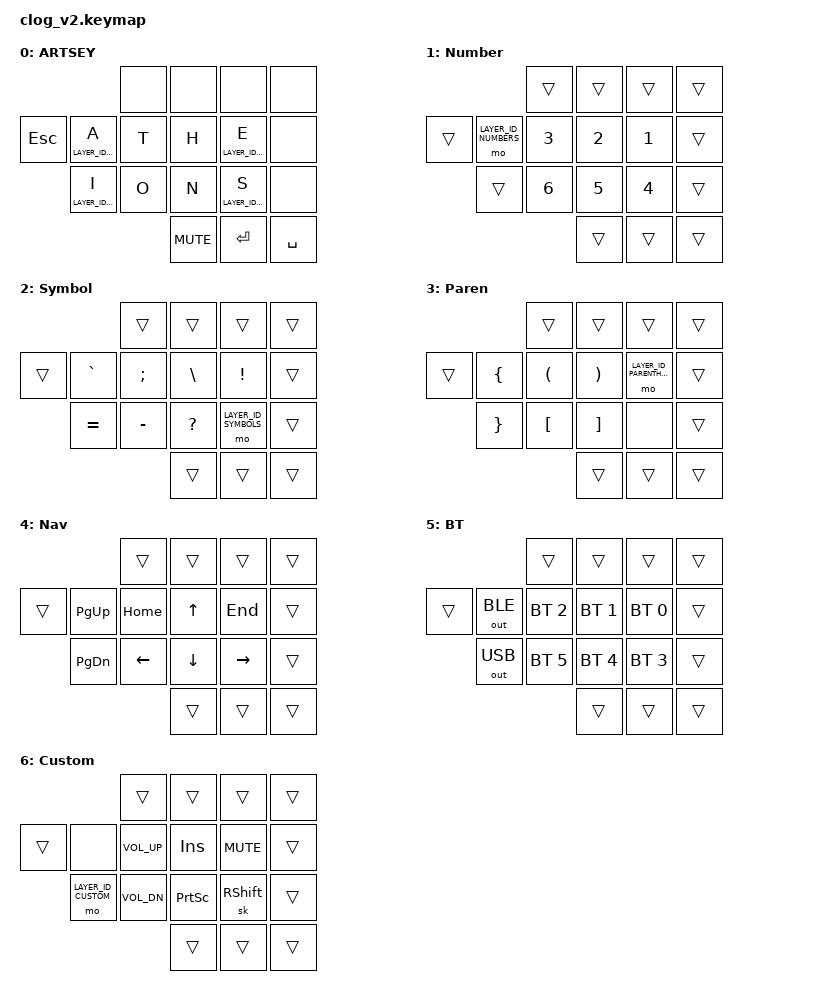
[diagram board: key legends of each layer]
#include <behaviors.dtsi>
#include <dt-bindings/zmk/keys.h>
#include <dt-bindings/zmk/bt.h>

#define KEY_E 8
#define KEY_H 7
#define KEY_T 6
#define KEY_A 5
#define KEY_S 12
#define KEY_N 11
#define KEY_O 10
#define KEY_I 9

/*
 * Copyright (c) 2021 Mike "KemoNine" Crosson
 *
 * SPDX-License-Identifier: MIT
 */

#include <behaviors.dtsi>
#include <dt-bindings/zmk/keys.h>
#include <dt-bindings/zmk/outputs.h>

/*****************************************
 * Setting up ARTSEY comboing
 *   - Enabled right OR left handed orientation
 *   - Please note: A/E key positions should be on your INDEX finger
 *     - The online reference is for right handed use
 *     - When using the ARTSEY layout left handed you'll want to ensure your keypositions are flipped along the Y axis
 *   - Update/adjust the key positions using your boards keymap 
 *     - See below for additional details
 *   - YOU MUST SET THE FOLLOWING CONFIG VALUES FOR THIS SETUP TO WORK PROPERLY IN YOUR BOARDS .conf FILE
 *     - CONFIG_ZMK_COMBO_MAX_COMBOS_PER_KEY=16
 *     - CONFIG_ZMK_COMBO_MAX_KEYS_PER_COMBO=8
 *     - CONFIG_ZMK_COMBO_MAX_PRESSED_COMBOS=8
 *****************************************/

// ARTS Row
// #define 8 0
// #define 7 1
// #define 6 2
// #define 3 3
// EYIO Row
// #define 12 4
// #define 11 5
// #define 10 6
// #define 9 7

/*****************************************
 * Define custom BT layer extra keys
 *
 * You can override the 2 blank keys on the BT select layer by copy/pasting the below into your keymap
 *     *before* including the artsey.dtsfile
 * Once added to your keymap you can adjust these 2 keys as you see fit
*****************************************/
#if !defined ARTSEY_BT_TOP
#define ARTSEY_BT_TOP &out OUT_BLE
#endif
#if !defined ARTSEY_BT_BOTTOM
#define ARTSEY_BT_BOTTOM &out OUT_USB
#endif

/*****************************************
 * Define how long it takes for the combos/holds to 'time out'
 * See documentation on "combos" for more detail
 * THE COMBO TIMEOUTS MUST BE THE SAME
 *    https://github.com/zmkfirmware/zmk/issues/905
 *****************************************/
#if !defined TIMEOUT_COMBO_2
#define TIMEOUT_COMBO_2 175
#endif
#if !defined TIMEOUT_COMBO_3
#define TIMEOUT_COMBO_3 175
#endif
#if !defined TIMEOUT_COMBO_4
#define TIMEOUT_COMBO_4 175
#endif
#if !defined TIMEOUT_LAYER_HOLD
#define TIMEOUT_LAYER_HOLD 200
#endif
#if !defined TIMEOUT_STICKY_LEADER_KEY
#define TIMEOUT_STICKY_LEADER_KEY 5000
#endif
&sk {
	release-after-ms = <TIMEOUT_STICKY_LEADER_KEY>;
};
&sl { 
	release-after-ms = <TIMEOUT_STICKY_LEADER_KEY>;
};

/*****************************************
 * Define custom layer
 *
 * You can override this layer by copy/pasting the into your keymap *before* including the artsey.dtsi file
 * Once added to your keymap you can adjust as you see fit
*****************************************/

/*****************************************
 * Layer IDs used by the ARTSEY keymap
 * Do NOT change these and do NOT change the order of the layers as shown below
 *****************************************/
#define LAYER_ID_GLOBAL -1
#define LAYER_ID_BASE 0
#define LAYER_ID_NUMBERS 1
#define LAYER_ID_SYMBOLS 2
#define LAYER_ID_PARENTHETICALS 3
#define LAYER_ID_NAVIGATION 4
#define LAYER_ID_BT_SEL 5
#define LAYER_ID_CUSTOM 6
#define LAYER_ID_BIG_SYM 7
#define LAYER_ID_BIG_FUNCTION 8

/*****************************************
 * Standard ARTSEY combo definitions
 * These should NOT be changed and are global in scope
 *****************************************/
/ {
	combos {
		compatible = "zmk,combos";
		/*****************************************
		 * 2 key combos
		 *****************************************/
		combo_enter      { timeout-ms = <TIMEOUT_COMBO_2>; key-positions = <8 12>; bindings = <&kp ENTER>; };
		combo_control    { timeout-ms = <TIMEOUT_COMBO_2>; key-positions = <12 3>; bindings = <&sk LCTRL>; };
		combo_gui        { timeout-ms = <TIMEOUT_COMBO_2>; key-positions = <11 3>; bindings = <&sk LGUI>; };
		combo_alt        { timeout-ms = <TIMEOUT_COMBO_2>; key-positions = <10 3>; bindings = <&sk LALT>; };
		combo_backspace  { timeout-ms = <TIMEOUT_COMBO_2>; key-positions = <12 7>; bindings = <&kp BACKSPACE>; };
		combo_delete     { timeout-ms = <TIMEOUT_COMBO_2>; key-positions = <10 7>; bindings = <&kp DELETE>; };
		combo_shift_lock { timeout-ms = <TIMEOUT_COMBO_2>; key-positions = <7 11>; bindings = <&kp LSHFT>; };

		combo_b           { layers = <LAYER_ID_BASE>; timeout-ms = <TIMEOUT_COMBO_2>; key-positions = <12 9>; bindings = <&kp B>; };
		combo_c           { layers = <LAYER_ID_BASE>; timeout-ms = <TIMEOUT_COMBO_2>; key-positions = <12 11>; bindings = <&kp C>; };
		combo_n           { layers = <LAYER_ID_BASE>; timeout-ms = <TIMEOUT_COMBO_2>; key-positions = <10 9>; bindings = <&kp Y>; };
		combo_f           { layers = <LAYER_ID_BASE>; timeout-ms = <TIMEOUT_COMBO_2>; key-positions = <8 7>; bindings = <&kp F>; };
		combo_g           { layers = <LAYER_ID_BASE>; timeout-ms = <TIMEOUT_COMBO_2>; key-positions = <7 6>; bindings = <&kp G>; };
		combo_u           { layers = <LAYER_ID_BASE>; timeout-ms = <TIMEOUT_COMBO_2>; key-positions = <11 10>; bindings = <&kp U>; };
		combo_h           { layers = <LAYER_ID_BASE>; timeout-ms = <TIMEOUT_COMBO_2>; key-positions = <12 10>; bindings = <&kp R>; };
		combo_v           { layers = <LAYER_ID_BASE>; timeout-ms = <TIMEOUT_COMBO_2>; key-positions = <7 3>; bindings = <&kp V>; };
		combo_j           { layers = <LAYER_ID_BASE>; timeout-ms = <TIMEOUT_COMBO_2>; key-positions = <6 3>; bindings = <&kp J>; };
		combo_w           { layers = <LAYER_ID_BASE>; timeout-ms = <TIMEOUT_COMBO_2>; key-positions = <8 3>; bindings = <&kp W>; };
		combo_k           { layers = <LAYER_ID_BASE>; timeout-ms = <TIMEOUT_COMBO_2>; key-positions = <11 9>; bindings = <&kp K>; };
		combo_comma       { layers = <LAYER_ID_BASE>; timeout-ms = <TIMEOUT_COMBO_2>; key-positions = <8 11>; bindings = <&kp COMMA>; };
		combo_period      { layers = <LAYER_ID_BASE>; timeout-ms = <TIMEOUT_COMBO_2>; key-positions = <8 10>; bindings = <&kp PERIOD>; };
		combo_slash       { layers = <LAYER_ID_BASE>; timeout-ms = <TIMEOUT_COMBO_2>; key-positions = <8 9>; bindings = <&kp SLASH>; };
		combo_exclamation { layers = <LAYER_ID_BASE>; timeout-ms = <TIMEOUT_COMBO_2>; key-positions = <6 10>; bindings = <&kp EXCL>; };
		
		combo_seven { layers = <LAYER_ID_NUMBERS>; timeout-ms = <TIMEOUT_COMBO_2>; key-positions = <8 7>; bindings = <&kp N7>; };
		combo_eight { layers = <LAYER_ID_NUMBERS>; timeout-ms = <TIMEOUT_COMBO_2>; key-positions = <7 6>; bindings = <&kp N8>; };
		combo_nine  { layers = <LAYER_ID_NUMBERS>; timeout-ms = <TIMEOUT_COMBO_2>; key-positions = <12 11>; bindings = <&kp N9>; };
		combo_zero  { layers = <LAYER_ID_NUMBERS>; timeout-ms = <TIMEOUT_COMBO_2>; key-positions = <11 10>; bindings = <&kp N0>; };

		/*****************************************
		 * 3 key combos
		 *****************************************/
		combo_esc              { timeout-ms = <TIMEOUT_COMBO_3>; key-positions = <8 7 9>; bindings = <&kp ESC>; };
		combo_layer_navigation { timeout-ms = <TIMEOUT_COMBO_3>; key-positions = <7 12 10>; bindings = <&tog LAYER_ID_NAVIGATION>; };

		combo_m            { layers = <LAYER_ID_BASE>; timeout-ms = <TIMEOUT_COMBO_3>; key-positions = <11 10 9>; bindings = <&kp M>; };
		combo_d            { layers = <LAYER_ID_BASE>; timeout-ms = <TIMEOUT_COMBO_3>; key-positions = <8 7 6>; bindings = <&kp D>; };
		combo_p            { layers = <LAYER_ID_BASE>; timeout-ms = <TIMEOUT_COMBO_3>; key-positions = <12 10 9>; bindings = <&kp P>; };
		combo_q            { layers = <LAYER_ID_BASE>; timeout-ms = <TIMEOUT_COMBO_3>; key-positions = <8 6 3>; bindings = <&kp Q>; };
		combo_x            { layers = <LAYER_ID_BASE>; timeout-ms = <TIMEOUT_COMBO_3>; key-positions = <7 6 3>; bindings = <&kp X>; };
		combo_l            { layers = <LAYER_ID_BASE>; timeout-ms = <TIMEOUT_COMBO_3>; key-positions = <12 11 10>; bindings = <&kp L>; };
		combo_single_quote { layers = <LAYER_ID_BASE>; timeout-ms = <TIMEOUT_COMBO_3>; key-positions = <8 11 10>; bindings = <&kp SQT>; };
		
		/*****************************************
		 * 4 key combos
		 *****************************************/
		combo_tab             { timeout-ms = <TIMEOUT_COMBO_4>; key-positions = <8 7 6 9>; bindings = <&kp TAB>; };
		combo_space           { timeout-ms = <TIMEOUT_COMBO_4>; key-positions = <12 11 10 9>; bindings = <&kp SPACE>; };
		combo_shift           { timeout-ms = <TIMEOUT_COMBO_4>; key-positions = <12 7 6 3>; bindings = <&sk LSHFT>; };
		combo_layer_bt_select { timeout-ms = <TIMEOUT_COMBO_4>; key-positions = <8 12 3 9>; bindings = <&tog LAYER_ID_BT_SEL>; };
		combo_bt_clr          { timeout-ms = <TIMEOUT_COMBO_4>; key-positions = <7 11 6 10>; bindings = <&bt BT_CLR>; };

		combo_z         { layers = <LAYER_ID_BASE>; timeout-ms = <TIMEOUT_COMBO_4>; key-positions = <8 7 6 3>; bindings = <&kp Z>; };
		combo_caps_lock { layers = <LAYER_ID_BASE>; timeout-ms = <TIMEOUT_COMBO_4>; key-positions = <9 10 11 8>; bindings = <&kp CAPS>; };
	};
};

/*****************************************
 * Standard ARTSEY layer activation definitions
 * These should NOT be changed and are global in scope
 *****************************************/
/ {
	behaviors {
		layer_base_kp: layer_base_kp { compatible = "zmk,behavior-hold-tap"; label = "layer_base_kp"; 
						#binding-cells = <2>; tapping_term_ms = <TIMEOUT_LAYER_HOLD>; flavor = "tap-preferred"; 
						bindings = <&mo>, <&kp>; };
		layer_numbers_kp: layer_numbers_kp { compatible = "zmk,behavior-hold-tap"; label = "layer_numbers_kp"; 
						#binding-cells = <2>; tapping_term_ms = <TIMEOUT_LAYER_HOLD>; flavor = "tap-preferred"; 
						bindings = <&mo>, <&kp>; };
		layer_symbols_kp: layer_symbols_kp { compatible = "zmk,behavior-hold-tap"; label = "layer_symbols_kp"; 
						#binding-cells = <2>; tapping_term_ms = <TIMEOUT_LAYER_HOLD>; flavor = "tap-preferred"; 
						bindings = <&mo>, <&kp>; };
		layer_parentheticals_kp: layer_parentheticals_kp { compatible = "zmk,behavior-hold-tap"; label = "layer_parentheticals_kp";
						#binding-cells = <2>; tapping_term_ms = <TIMEOUT_LAYER_HOLD>; flavor = "tap-preferred";
						bindings = <&mo>, <&kp>; };
		layer_custom_kp: layer_custom_kp { compatible = "zmk,behavior-hold-tap"; label = "layer_custom_kp";
						#binding-cells = <2>; tapping_term_ms = <TIMEOUT_LAYER_HOLD>; flavor = "tap-preferred";
						bindings = <&mo>, <&kp>; };
		ctrl_alt_kp: ctrl_alt_kp { compatible = "zmk,behavior-hold-tap"; label = "ctrl_alt_kp";
						#binding-cells = <2>; tapping_term_ms = <TIMEOUT_LAYER_HOLD>; flavor = "tap-preferred";
						bindings = <&sk>, <&sk>; };
	};
};



/ {
    keymap {
        compatible = "zmk,keymap";
        base {
            label = "ARTSEY";
            bindings = <
                                                         &none &none       &none                                              &none
            &kp ESC &layer_numbers_kp LAYER_ID_NUMBERS A &kp T &kp H       &layer_parentheticals_kp LAYER_ID_PARENTHETICALS E &none
                    &layer_custom_kp LAYER_ID_CUSTOM I   &kp O &kp N       &layer_symbols_kp LAYER_ID_SYMBOLS S               &none
                                                               &kp C_MUTE  &kp ENTER                                          &kp SPC
            >;

			sensor-bindings = <&inc_dec_kp PG_DN PG_UP>;
        };
		numbers {
			label = "Number";
			bindings = <
				                         &trans &trans &trans &trans
			&trans &mo LAYER_ID_NUMBERS  &kp N3 &kp N2 &kp N1 &trans
				   &trans                &kp N6 &kp N5 &kp N4 &trans
                                                &trans &trans &trans
				
			>;
		};
		symbols {
			label = "Symbol";
			bindings = <
				             &trans    &trans    &trans               &trans
			&trans &kp GRAVE &kp SEMI  &kp BSLH  &kp EXCL             &trans
				   &kp EQUAL &kp MINUS &kp QMARK &mo LAYER_ID_SYMBOLS &trans
                                       &trans    &trans               &trans
			>;
		};
		parentheticals {
			label = "Paren";
			bindings = <
			                &trans   &trans   &trans                      &trans
			&trans &kp LBRC &kp LPAR &kp RPAR &mo LAYER_ID_PARENTHETICALS &trans
			       &kp RBRC &kp LBKT &kp RBKT &none                       &trans
                                     &trans   &trans                      &trans
			>;
		};
		navigation {
			label = "Nav";
			bindings = <
				             &trans   &trans   &trans    &trans
			&trans &kp PG_UP &kp HOME &kp UP   &kp END   &trans
				   &kp PG_DN &kp LEFT &kp DOWN &kp RIGHT &trans
				                      &trans   &trans    &trans
			>;
		};
		bt {
			label = "BT";
			bindings = <
				                    &trans       &trans       &trans       &trans
			&trans ARTSEY_BT_TOP    &bt BT_SEL 2 &bt BT_SEL 1 &bt BT_SEL 0 &trans
				   ARTSEY_BT_BOTTOM &bt BT_SEL 5 &bt BT_SEL 4 &bt BT_SEL 3 &trans
				                                 &trans       &trans       &trans
			>;
		};
        custom {                                                       \
			label = "Custom";                                          \
			bindings = <
				                       &trans        &trans    &trans     &trans                                          \
			&trans &none               &kp C_VOL_UP  &kp INS   &kp C_MUTE &trans
				   &mo LAYER_ID_CUSTOM &kp C_VOL_DN  &kp PSCRN &sk RSHFT  &trans
				                                 &trans       &trans       &trans
			>;
		};
	};
};

